AUTOSAR XML (schema 4-2-2)
package /STELLANTIS/EPT/ASWCs
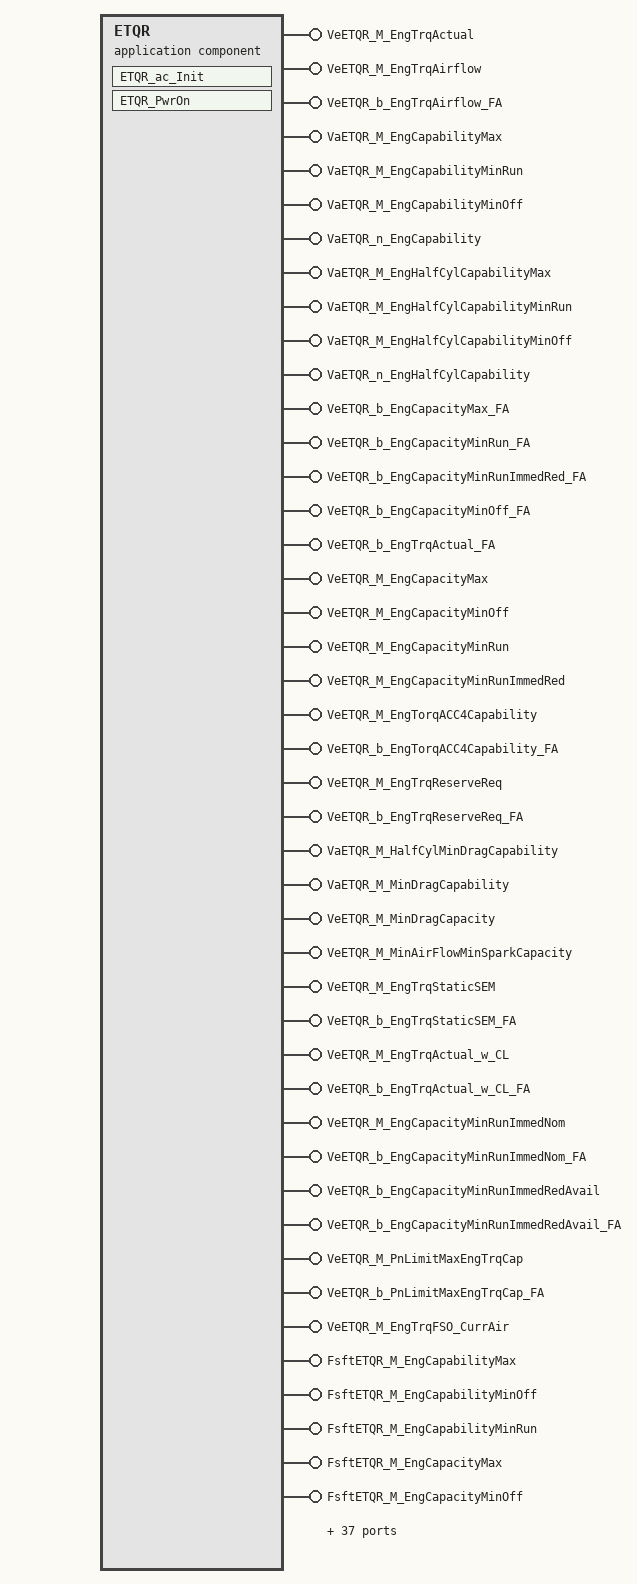
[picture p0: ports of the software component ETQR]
  application sw component type ETQR
    81 x provide port:
      VeETQR_M_EngTrqActual: nonqueued-sender-com-spec{data-element=Value, init-value=0}, provided-interface=VeETQR_M_EngTrqActual
      VeETQR_M_EngTrqAirflow: nonqueued-sender-com-spec{data-element=Value, init-value=0}, provided-interface=VeETQR_M_EngTrqAirflow
      VeETQR_b_EngTrqAirflow_FA: nonqueued-sender-com-spec{data-element=Value, init-value=0}, provided-interface=VeETQR_b_EngTrqAirflow_FA
      VaETQR_M_EngCapabilityMax: nonqueued-sender-com-spec{data-element=Value, init-value=16 x 0}, provided-interface=VaETQR_M_EngCapabilityMax
      VaETQR_M_EngCapabilityMinRun: nonqueued-sender-com-spec{data-element=Value, init-value=16 x 0}, provided-interface=VaETQR_M_EngCapabilityMinRun
      VaETQR_M_EngCapabilityMinOff: nonqueued-sender-com-spec{data-element=Value, init-value=16 x 0}, provided-interface=VaETQR_M_EngCapabilityMinOff
      VaETQR_n_EngCapability: nonqueued-sender-com-spec{data-element=Value, init-value=16 x 0}, provided-interface=VaETQR_n_EngCapability
      VaETQR_M_EngHalfCylCapabilityMax: nonqueued-sender-com-spec{data-element=Value, init-value=16 x 0}, provided-interface=VaETQR_M_EngHalfCylCapabilityMax
      VaETQR_M_EngHalfCylCapabilityMinRun: nonqueued-sender-com-spec{data-element=Value, init-value=16 x 0}, provided-interface=VaETQR_M_EngHalfCylCapabilityMinRun
      VaETQR_M_EngHalfCylCapabilityMinOff: nonqueued-sender-com-spec{data-element=Value, init-value=16 x 0}, provided-interface=VaETQR_M_EngHalfCylCapabilityMinOff
      VaETQR_n_EngHalfCylCapability: nonqueued-sender-com-spec{data-element=Value, init-value=16 x 0}, provided-interface=VaETQR_n_EngHalfCylCapability
      VeETQR_b_EngCapacityMax_FA: nonqueued-sender-com-spec{data-element=Value, init-value=0}, provided-interface=VeETQR_b_EngCapacityMax_FA
      VeETQR_b_EngCapacityMinRun_FA: nonqueued-sender-com-spec{data-element=Value, init-value=0}, provided-interface=VeETQR_b_EngCapacityMinRun_FA
      VeETQR_b_EngCapacityMinRunImmedRed_FA: nonqueued-sender-com-spec{data-element=Value, init-value=0}, provided-interface=VeETQR_b_EngCapacityMinRunImmedRed_FA
      VeETQR_b_EngCapacityMinOff_FA: nonqueued-sender-com-spec{data-element=Value, init-value=0}, provided-interface=VeETQR_b_EngCapacityMinOff_FA
      VeETQR_b_EngTrqActual_FA: nonqueued-sender-com-spec{data-element=Value, init-value=0}, provided-interface=VeETQR_b_EngTrqActual_FA
      VeETQR_M_EngCapacityMax: nonqueued-sender-com-spec{data-element=Value, init-value=0}, provided-interface=VeETQR_M_EngCapacityMax
      VeETQR_M_EngCapacityMinOff: nonqueued-sender-com-spec{data-element=Value, init-value=0}, provided-interface=VeETQR_M_EngCapacityMinOff
      VeETQR_M_EngCapacityMinRun: nonqueued-sender-com-spec{data-element=Value, init-value=0}, provided-interface=VeETQR_M_EngCapacityMinRun
      VeETQR_M_EngCapacityMinRunImmedRed: nonqueued-sender-com-spec{data-element=Value, init-value=0}, provided-interface=VeETQR_M_EngCapacityMinRunImmedRed
      VeETQR_M_EngTorqACC4Capability: nonqueued-sender-com-spec{data-element=Value, init-value=0}, provided-interface=VeETQR_M_EngTorqACC4Capability
      VeETQR_b_EngTorqACC4Capability_FA: nonqueued-sender-com-spec{data-element=Value, init-value=0}, provided-interface=VeETQR_b_EngTorqACC4Capability_FA
      VeETQR_M_EngTrqReserveReq: nonqueued-sender-com-spec{data-element=Value, init-value=0}, provided-interface=VeETQR_M_EngTrqReserveReq
      VeETQR_b_EngTrqReserveReq_FA: nonqueued-sender-com-spec{data-element=Value, init-value=0}, provided-interface=VeETQR_b_EngTrqReserveReq_FA
      VaETQR_M_HalfCylMinDragCapability: nonqueued-sender-com-spec{data-element=Value, init-value=16 x 0}, provided-interface=VaETQR_M_HalfCylMinDragCapability
      VaETQR_M_MinDragCapability: nonqueued-sender-com-spec{data-element=Value, init-value=16 x 0}, provided-interface=VaETQR_M_MinDragCapability
      VeETQR_M_MinDragCapacity: nonqueued-sender-com-spec{data-element=Value, init-value=0}, provided-interface=VeETQR_M_MinDragCapacity
      VeETQR_M_MinAirFlowMinSparkCapacity: nonqueued-sender-com-spec{data-element=Value, init-value=0}, provided-interface=VeETQR_M_MinAirFlowMinSparkCapacity
      VeETQR_M_EngTrqStaticSEM: nonqueued-sender-com-spec{data-element=Value, init-value=0}, provided-interface=VeETQR_M_EngTrqStaticSEM
      VeETQR_b_EngTrqStaticSEM_FA: nonqueued-sender-com-spec{data-element=Value, init-value=0}, provided-interface=VeETQR_b_EngTrqStaticSEM_FA
      VeETQR_M_EngTrqActual_w_CL: nonqueued-sender-com-spec{data-element=Value, init-value=0}, provided-interface=VeETQR_M_EngTrqActual_w_CL
      VeETQR_b_EngTrqActual_w_CL_FA: nonqueued-sender-com-spec{data-element=Value, init-value=0}, provided-interface=VeETQR_b_EngTrqActual_w_CL_FA
      VeETQR_M_EngCapacityMinRunImmedNom: nonqueued-sender-com-spec{data-element=Value, init-value=0}, provided-interface=VeETQR_M_EngCapacityMinRunImmedNom
      VeETQR_b_EngCapacityMinRunImmedNom_FA: nonqueued-sender-com-spec{data-element=Value, init-value=0}, provided-interface=VeETQR_b_EngCapacityMinRunImmedNom_FA
      VeETQR_b_EngCapacityMinRunImmedRedAvail: nonqueued-sender-com-spec{data-element=Value, init-value=0}, provided-interface=VeETQR_b_EngCapacityMinRunImmedRedAvail
      VeETQR_b_EngCapacityMinRunImmedRedAvail_FA: nonqueued-sender-com-spec{data-element=Value, init-value=0}, provided-interface=VeETQR_b_EngCapacityMinRunImmedRedAvail_FA
      VeETQR_M_PnLimitMaxEngTrqCap: nonqueued-sender-com-spec{data-element=Value, init-value=0}, provided-interface=VeETQR_M_PnLimitMaxEngTrqCap
      VeETQR_b_PnLimitMaxEngTrqCap_FA: nonqueued-sender-com-spec{data-element=Value, init-value=0}, provided-interface=VeETQR_b_PnLimitMaxEngTrqCap_FA
      VeETQR_M_EngTrqFSO_CurrAir: nonqueued-sender-com-spec{data-element=Value, init-value=0}, provided-interface=VeETQR_M_EngTrqFSO_CurrAir
      FsftETQR_M_EngCapabilityMax: server-com-spec=FsftETQR_M_EngCapabilityMax, provided-interface=FsftETQR_M_EngCapabilityMax
      FsftETQR_M_EngCapabilityMinOff: server-com-spec=FsftETQR_M_EngCapabilityMinOff, provided-interface=FsftETQR_M_EngCapabilityMinOff
      FsftETQR_M_EngCapabilityMinRun: server-com-spec=FsftETQR_M_EngCapabilityMinRun, provided-interface=FsftETQR_M_EngCapabilityMinRun
      FsftETQR_M_EngCapacityMax: server-com-spec=FsftETQR_M_EngCapacityMax, provided-interface=FsftETQR_M_EngCapacityMax
      FsftETQR_M_EngCapacityMinOff: server-com-spec=FsftETQR_M_EngCapacityMinOff, provided-interface=FsftETQR_M_EngCapacityMinOff
      FsftETQR_M_EngCapacityMinRun: server-com-spec=FsftETQR_M_EngCapacityMinRun, provided-interface=FsftETQR_M_EngCapacityMinRun
      FsftETQR_M_EngCapacityMinRunImmedNom: server-com-spec=FsftETQR_M_EngCapacityMinRunImmedNom, provided-interface=FsftETQR_M_EngCapacityMinRunImmedNom
      FsftETQR_M_EngCapacityMinRunImmedRed: server-com-spec=FsftETQR_M_EngCapacityMinRunImmedRed, provided-interface=FsftETQR_M_EngCapacityMinRunImmedRed
      FsftETQR_M_EngTorqACC4Capability: server-com-spec=FsftETQR_M_EngTorqACC4Capability, provided-interface=FsftETQR_M_EngTorqACC4Capability
      FsftETQR_M_EngTorque: server-com-spec=FsftETQR_M_EngTorque, provided-interface=FsftETQR_M_EngTorque
      FsftETQR_M_EngTrqActual: server-com-spec=FsftETQR_M_EngTrqActual, provided-interface=FsftETQR_M_EngTrqActual
      FsftETQR_M_EngTrqAirflow: server-com-spec=FsftETQR_M_EngTrqAirflow, provided-interface=FsftETQR_M_EngTrqAirflow
      FsftETQR_M_EngTrqFSO_CurrAir: server-com-spec=FsftETQR_M_EngTrqFSO_CurrAir, provided-interface=FsftETQR_M_EngTrqFSO_CurrAir
      FsftETQR_M_EngTrqReserveReq: server-com-spec=FsftETQR_M_EngTrqReserveReq, provided-interface=FsftETQR_M_EngTrqReserveReq
      FsftETQR_M_EngTrqStaticSEM: server-com-spec=FsftETQR_M_EngTrqStaticSEM, provided-interface=FsftETQR_M_EngTrqStaticSEM
      FsftETQR_M_MinAirFlowMinSparkCapacity: server-com-spec=FsftETQR_M_MinAirFlowMinSparkCapacity, provided-interface=FsftETQR_M_MinAirFlowMinSparkCapacity
      FsftETQR_M_MinDragCapability: server-com-spec=FsftETQR_M_MinDragCapability, provided-interface=FsftETQR_M_MinDragCapability
      FsftETQR_M_MinDragCapacity: server-com-spec=FsftETQR_M_MinDragCapacity, provided-interface=FsftETQR_M_MinDragCapacity
      FsftETQR_M_PnLimitMaxEngTrqCap: server-com-spec=FsftETQR_M_PnLimitMaxEngTrqCap, provided-interface=FsftETQR_M_PnLimitMaxEngTrqCap
      FsftETQR_b_EngCapacityMinRunImmedRedAvail: server-com-spec=FsftETQR_b_EngCapacityMinRunImmedRedAvail, provided-interface=FsftETQR_b_EngCapacityMinRunImmedRedAvail
      FsftETQR_n_EngCapability: server-com-spec=FsftETQR_n_EngCapability, provided-interface=FsftETQR_n_EngCapability
      PokeETQR_M_EngCapabilityMax: server-com-spec{operation=PokeETQR_M_EngCapabilityMax, queue-length=1}, provided-interface=PokeETQR_M_EngCapabilityMax
      PokeETQR_M_EngCapabilityMinOff: server-com-spec{operation=PokeETQR_M_EngCapabilityMinOff, queue-length=1}, provided-interface=PokeETQR_M_EngCapabilityMinOff
      PokeETQR_M_EngCapabilityMinRun: server-com-spec{operation=PokeETQR_M_EngCapabilityMinRun, queue-length=1}, provided-interface=PokeETQR_M_EngCapabilityMinRun
      PokeETQR_M_EngCapacityMax: server-com-spec{operation=PokeETQR_M_EngCapacityMax, queue-length=1}, provided-interface=PokeETQR_M_EngCapacityMax
      PokeETQR_M_EngCapacityMinOff: server-com-spec{operation=PokeETQR_M_EngCapacityMinOff, queue-length=1}, provided-interface=PokeETQR_M_EngCapacityMinOff
      PokeETQR_M_EngCapacityMinRun: server-com-spec{operation=PokeETQR_M_EngCapacityMinRun, queue-length=1}, provided-interface=PokeETQR_M_EngCapacityMinRun
      PokeETQR_M_EngCapacityMinRunImmedNom: server-com-spec{operation=PokeETQR_M_EngCapacityMinRunImmedNom, queue-length=1}, provided-interface=PokeETQR_M_EngCapacityMinRunImmedNom
      PokeETQR_M_EngCapacityMinRunImmedRed: server-com-spec{operation=PokeETQR_M_EngCapacityMinRunImmedRed, queue-length=1}, provided-interface=PokeETQR_M_EngCapacityMinRunImmedRed
      PokeETQR_M_EngTorqACC4Capability: server-com-spec{operation=PokeETQR_M_EngTorqACC4Capability, queue-length=1}, provided-interface=PokeETQR_M_EngTorqACC4Capability
      PokeETQR_M_EngTorque: server-com-spec{operation=PokeETQR_M_EngTorque, queue-length=1}, provided-interface=PokeETQR_M_EngTorque
      PokeETQR_M_EngTrqActual: server-com-spec{operation=PokeETQR_M_EngTrqActual, queue-length=1}, provided-interface=PokeETQR_M_EngTrqActual
      PokeETQR_M_EngTrqAirflow: server-com-spec{operation=PokeETQR_M_EngTrqAirflow, queue-length=1}, provided-interface=PokeETQR_M_EngTrqAirflow
      PokeETQR_M_EngTrqFSO_CurrAir: server-com-spec{operation=PokeETQR_M_EngTrqFSO_CurrAir, queue-length=1}, provided-interface=PokeETQR_M_EngTrqFSO_CurrAir
      PokeETQR_M_EngTrqReserveReq: server-com-spec{operation=PokeETQR_M_EngTrqReserveReq, queue-length=1}, provided-interface=PokeETQR_M_EngTrqReserveReq
      PokeETQR_M_EngTrqStaticSEM: server-com-spec{operation=PokeETQR_M_EngTrqStaticSEM, queue-length=1}, provided-interface=PokeETQR_M_EngTrqStaticSEM
      PokeETQR_M_MinAirFlowMinSparkCapacity: server-com-spec{operation=PokeETQR_M_MinAirFlowMinSparkCapacity, queue-length=1}, provided-interface=PokeETQR_M_MinAirFlowMinSparkCapacity
      PokeETQR_M_MinDragCapability: server-com-spec{operation=PokeETQR_M_MinDragCapability, queue-length=1}, provided-interface=PokeETQR_M_MinDragCapability
      PokeETQR_M_MinDragCapacity: server-com-spec{operation=PokeETQR_M_MinDragCapacity, queue-length=1}, provided-interface=PokeETQR_M_MinDragCapacity
      PokeETQR_M_PnLimitMaxEngTrqCap: server-com-spec{operation=PokeETQR_M_PnLimitMaxEngTrqCap, queue-length=1}, provided-interface=PokeETQR_M_PnLimitMaxEngTrqCap
      PokeETQR_b_EngCapacityMinRunImmedRedAvail: server-com-spec{operation=PokeETQR_b_EngCapacityMinRunImmedRedAvail, queue-length=1}, provided-interface=PokeETQR_b_EngCapacityMinRunImmedRedAvail
      PokeETQR_n_EngCapability: server-com-spec{operation=PokeETQR_n_EngCapability, queue-length=1}, provided-interface=PokeETQR_n_EngCapability
    behavior IB_ETQR: data-type-mapping=msADTtoIDTMapping, handle-termination-and-restart=NO-SUPPORT
      init event Event_ETQR_ac_Init: start-on-event=ETQR_ac_Init
      init event Event_PwrOn: start-on-event=ETQR_PwrOn
      explicit-inter-runnable-variables:
        40 x data, all with sw-calibration-access=READ-ONLY:
          VeETQI_M_EngTrqActual_write_IRV: category=VALUE, type=Float, init-value=0
          VeETQI_b_EngTrqActual_FA_write_IRV: category=VALUE, type=Boolean, init-value=0
          VeETQI_b_EngTrqAirflow_FA_write_IRV: category=VALUE, type=Boolean, init-value=0
          VeETQI_M_EngTrqAirflow_write_IRV: category=VALUE, type=Float, init-value=0
          VeETQI_M_EngTrqStaticSEM_write_IRV: category=VALUE, type=Float, init-value=0
          VeETQI_b_EngTrqStaticSEM_FA_write_IRV: category=VALUE, type=Boolean, init-value=0
          VeETQI_M_EngTorque_write_IRV: category=VALUE, type=Float, init-value=0
          VeETQI_b_EngTorque_FA_write_IRV: category=VALUE, type=Boolean, init-value=0
          VeETQI_b_EngCapacityMax_FA_write_IRV: category=VALUE, type=Boolean, init-value=0
          EngCapabilityMax_x10ms_write_IRV: category=ARRAY, type=rt_Array_Float_16, init-value=16 x 0
          VeETQI_M_EngCapacityMax_write_IRV: category=VALUE, type=Float, init-value=0
          VeETQI_b_EngCapacityMinOff_FA_write_IRV: category=VALUE, type=Boolean, init-value=0
          VeETQI_b_EngCapacityMinRunImmed_FA_write_IRV: category=VALUE, type=Boolean, init-value=0
          VeETQI_b_EngCapacityMinRun_FA_write_IRV: category=VALUE, type=Boolean, init-value=0
          VeETQI_M_EngCapacityMinRun_write_IRV: category=VALUE, type=Float, init-value=0
          VeETQI_M_EngCapacityMinRunImmed_write_IRV: category=VALUE, type=Float, init-value=0
          VeETQI_M_EngCapacityMinOff_write_IRV: category=VALUE, type=Float, init-value=0
          VaETQI_M_EngCapabilityMinRun_write_IRV: category=ARRAY, type=rt_Array_Float_16, init-value=16 x 0
          EngCapabilityMinOff_x10ms_write_IRV: category=ARRAY, type=rt_Array_Float_16, init-value=16 x 0
          VaETQI_n_EngCapability_write_IRV: category=ARRAY, type=rt_Array_Float_16, init-value=16 x 0
          EngHalfCylCapabilityMax_x10ms_write_IRV: category=ARRAY, type=rt_Array_Float_16, init-value=16 x 0
          VaETQI_M_EngHalfCylCapabilityMinRun_write_IRV: category=ARRAY, type=rt_Array_Float_16, init-value=16 x 0
          EngHalfCylCapabilityMinOff_x10ms_write_IRV: category=ARRAY, type=rt_Array_Float_16, init-value=16 x 0
          VaETQI_n_EngHalfCylCapability_write_IRV: category=ARRAY, type=rt_Array_Float_16, init-value=16 x 0
          VeETQI_M_MinDragCapacity_write_IRV: category=VALUE, type=Float, init-value=0
          VeETQI_b_MinDragCapacity_FA_write_IRV: category=VALUE, type=Boolean, init-value=0
          VaETQI_M_MinDragCapability_write_IRV: category=ARRAY, type=rt_Array_Float_16, init-value=16 x 0
          VaETQI_M_HalfCylMinDragCapability_write_IRV: category=ARRAY, type=rt_Array_Float_16, init-value=16 x 0
          VeETQI_M_MinAirFlowMinSparkCapacity_write_IRV: category=VALUE, type=Float, init-value=0
          VeETQI_b_MinAirFlowMinSparkCapacity_FA_write_IRV: category=VALUE, type=Boolean, init-value=0
          VeETQI_M_EngCapacityMinRunImmedNom_write_IRV: category=VALUE, type=Float, init-value=0
          VeETQI_b_EngCapacityMinRunImmedNom_FA_write_IRV: category=VALUE, type=Boolean, init-value=0
          VaETQI_M_EngCapabilityMax_write_IRV: category=ARRAY, type=rt_Array_Float_16, init-value=16 x 0
          VeETQI_Cnt_CapabilityFrame_Max_write_IRV: category=VALUE, type=Float, init-value=0
          VaETQI_M_EngHalfCylCapabilityMax_write_IRV: category=ARRAY, type=rt_Array_Float_16, init-value=16 x 0
          VeETQI_Cnt_CapabilityFrame_HalfCylMax_write_IRV: category=VALUE, type=Float, init-value=0
          VaETQI_M_EngCapabilityMinOff_write_IRV: category=ARRAY, type=rt_Array_Float_16, init-value=16 x 0
          VeETQI_Cnt_CapabilityFrame_Min_write_IRV: category=VALUE, type=Float, init-value=0
          VaETQI_M_EngHalfCylCapabilityMinOff_write_IRV: category=ARRAY, type=rt_Array_Float_16, init-value=16 x 0
          VeETQI_Cnt_CapabilityFrame_HalfCylMin_write_IRV: category=VALUE, type=Float, init-value=0
      runnable ETQR_ac_Init
        data-send-points:
          10 x access:
            OUT_VaETQR_M_EngCapabilityMax_Value: accessed-variable=VaETQR_M_EngCapabilityMax.Value
            OUT_VaETQR_M_EngCapabilityMinRun_Value: accessed-variable=VaETQR_M_EngCapabilityMinRun.Value
            OUT_VaETQR_M_EngCapabilityMinOff_Value: accessed-variable=VaETQR_M_EngCapabilityMinOff.Value
            OUT_VaETQR_n_EngCapability_Value: accessed-variable=VaETQR_n_EngCapability.Value
            OUT_VaETQR_M_EngHalfCylCapabilityMax_Value: accessed-variable=VaETQR_M_EngHalfCylCapabilityMax.Value
            OUT_VaETQR_M_EngHalfCylCapabilityMinRun_Value: accessed-variable=VaETQR_M_EngHalfCylCapabilityMinRun.Value
            OUT_VaETQR_M_EngHalfCylCapabilityMinOff_Value: accessed-variable=VaETQR_M_EngHalfCylCapabilityMinOff.Value
            OUT_VaETQR_n_EngHalfCylCapability_Value: accessed-variable=VaETQR_n_EngHalfCylCapability.Value
            OUT_VaETQR_M_HalfCylMinDragCapability_Value: accessed-variable=VaETQR_M_HalfCylMinDragCapability.Value
            OUT_VaETQR_M_MinDragCapability_Value: accessed-variable=VaETQR_M_MinDragCapability.Value
      runnable ETQR_PwrOn
        data-send-points:
          39 x access:
            OUT_VaETQR_M_EngCapabilityMinRun_Value: accessed-variable=VaETQR_M_EngCapabilityMinRun.Value
            OUT_VeETQR_b_PnLimitMaxEngTrqCap_FA_Value: accessed-variable=VeETQR_b_PnLimitMaxEngTrqCap_FA.Value
            OUT_VeETQR_M_PnLimitMaxEngTrqCap_Value: accessed-variable=VeETQR_M_PnLimitMaxEngTrqCap.Value
            OUT_VaETQR_M_EngHalfCylCapabilityMinRun_Value: accessed-variable=VaETQR_M_EngHalfCylCapabilityMinRun.Value
            OUT_VaETQR_n_EngCapability_Value: accessed-variable=VaETQR_n_EngCapability.Value
            OUT_VaETQR_n_EngHalfCylCapability_Value: accessed-variable=VaETQR_n_EngHalfCylCapability.Value
            OUT_VaETQR_M_MinDragCapability_Value: accessed-variable=VaETQR_M_MinDragCapability.Value
            OUT_VaETQR_M_HalfCylMinDragCapability_Value: accessed-variable=VaETQR_M_HalfCylMinDragCapability.Value
            OUT_VeETQR_b_EngCapacityMinRunImmedRedAvail_Value: accessed-variable=VeETQR_b_EngCapacityMinRunImmedRedAvail.Value
            OUT_VeETQR_b_EngCapacityMinRunImmedRedAvail_FA_Value: accessed-variable=VeETQR_b_EngCapacityMinRunImmedRedAvail_FA.Value
            OUT_VeETQR_b_EngCapacityMax_FA_Value: accessed-variable=VeETQR_b_EngCapacityMax_FA.Value
            OUT_VeETQR_b_EngCapacityMinRun_FA_Value: accessed-variable=VeETQR_b_EngCapacityMinRun_FA.Value
            OUT_VeETQR_b_EngCapacityMinRunImmedRed_FA_Value: accessed-variable=VeETQR_b_EngCapacityMinRunImmedRed_FA.Value
            OUT_VeETQR_b_EngCapacityMinOff_FA_Value: accessed-variable=VeETQR_b_EngCapacityMinOff_FA.Value
            OUT_VeETQR_b_EngTrqActual_FA_Value: accessed-variable=VeETQR_b_EngTrqActual_FA.Value
            OUT_VeETQR_b_EngTrqAirflow_FA_Value: accessed-variable=VeETQR_b_EngTrqAirflow_FA.Value
            OUT_VeETQR_M_EngTorqACC4Capability_Value: accessed-variable=VeETQR_M_EngTorqACC4Capability.Value
            OUT_VeETQR_b_EngTorqACC4Capability_FA_Value: accessed-variable=VeETQR_b_EngTorqACC4Capability_FA.Value
            OUT_VeETQR_b_EngTrqReserveReq_FA_Value: accessed-variable=VeETQR_b_EngTrqReserveReq_FA.Value
            OUT_VeETQR_M_EngTrqReserveReq_Value: accessed-variable=VeETQR_M_EngTrqReserveReq.Value
            OUT_VeETQR_M_EngTrqActual_Value: accessed-variable=VeETQR_M_EngTrqActual.Value
            OUT_VeETQR_M_EngTrqAirflow_Value: accessed-variable=VeETQR_M_EngTrqAirflow.Value
            OUT_VeETQR_b_EngTrqStaticSEM_FA_Value: accessed-variable=VeETQR_b_EngTrqStaticSEM_FA.Value
            OUT_VeETQR_M_EngTrqStaticSEM_Value: accessed-variable=VeETQR_M_EngTrqStaticSEM.Value
            OUT_VeETQR_M_MinAirFlowMinSparkCapacity_Value: accessed-variable=VeETQR_M_MinAirFlowMinSparkCapacity.Value
            OUT_VeETQR_M_MinDragCapacity_Value: accessed-variable=VeETQR_M_MinDragCapacity.Value
            OUT_VeETQR_M_EngCapacityMinRunImmedRed_Value: accessed-variable=VeETQR_M_EngCapacityMinRunImmedRed.Value
            OUT_VeETQR_M_EngCapacityMinRun_Value: accessed-variable=VeETQR_M_EngCapacityMinRun.Value
            OUT_VeETQR_b_EngCapacityMinRunImmedNom_FA_Value: accessed-variable=VeETQR_b_EngCapacityMinRunImmedNom_FA.Value
            OUT_VeETQR_M_EngCapacityMinRunImmedNom_Value: accessed-variable=VeETQR_M_EngCapacityMinRunImmedNom.Value
            OUT_VaETQR_M_EngCapabilityMax_Value: accessed-variable=VaETQR_M_EngCapabilityMax.Value
            OUT_VaETQR_M_EngCapabilityMinOff_Value: accessed-variable=VaETQR_M_EngCapabilityMinOff.Value
            OUT_VaETQR_M_EngHalfCylCapabilityMax_Value: accessed-variable=VaETQR_M_EngHalfCylCapabilityMax.Value
            OUT_VaETQR_M_EngHalfCylCapabilityMinOff_Value: accessed-variable=VaETQR_M_EngHalfCylCapabilityMinOff.Value
            OUT_VeETQR_M_EngCapacityMax_Value: accessed-variable=VeETQR_M_EngCapacityMax.Value
            OUT_VeETQR_M_EngCapacityMinOff_Value: accessed-variable=VeETQR_M_EngCapacityMinOff.Value
            OUT_VeETQR_M_EngTrqActual_w_CL_Value: accessed-variable=VeETQR_M_EngTrqActual_w_CL.Value
            OUT_VeETQR_b_EngTrqActual_w_CL_FA_Value: accessed-variable=VeETQR_b_EngTrqActual_w_CL_FA.Value
            OUT_VeETQR_M_EngTrqFSO_CurrAir_Value: accessed-variable=VeETQR_M_EngTrqFSO_CurrAir.Value
        written-local-variables:
          40 x access:
            WV_EngCapabilityMax_x10ms_write_IRV: accessed-variable=EngCapabilityMax_x10ms_write_IRV
            WV_EngCapabilityMinOff_x10ms_write_IRV: accessed-variable=EngCapabilityMinOff_x10ms_write_IRV
            WV_EngHalfCylCapabilityMax_x10ms_write_IRV: accessed-variable=EngHalfCylCapabilityMax_x10ms_write_IRV
            WV_EngHalfCylCapabilityMinOff_x10ms_write_IRV: accessed-variable=EngHalfCylCapabilityMinOff_x10ms_write_IRV
            WV_VaETQI_M_EngCapabilityMax_write_IRV: accessed-variable=VaETQI_M_EngCapabilityMax_write_IRV
            WV_VaETQI_M_EngCapabilityMinOff_write_IRV: accessed-variable=VaETQI_M_EngCapabilityMinOff_write_IRV
            WV_VaETQI_M_EngCapabilityMinRun_write_IRV: accessed-variable=VaETQI_M_EngCapabilityMinRun_write_IRV
            WV_VaETQI_M_EngHalfCylCapabilityMax_write_IRV: accessed-variable=VaETQI_M_EngHalfCylCapabilityMax_write_IRV
            WV_VaETQI_M_EngHalfCylCapabilityMinOff_write_IRV: accessed-variable=VaETQI_M_EngHalfCylCapabilityMinOff_write_IRV
            WV_VaETQI_M_EngHalfCylCapabilityMinRun_write_IRV: accessed-variable=VaETQI_M_EngHalfCylCapabilityMinRun_write_IRV
            WV_VaETQI_M_HalfCylMinDragCapability_write_IRV: accessed-variable=VaETQI_M_HalfCylMinDragCapability_write_IRV
            WV_VaETQI_M_MinDragCapability_write_IRV: accessed-variable=VaETQI_M_MinDragCapability_write_IRV
            WV_VaETQI_n_EngCapability_write_IRV: accessed-variable=VaETQI_n_EngCapability_write_IRV
            WV_VaETQI_n_EngHalfCylCapability_write_IRV: accessed-variable=VaETQI_n_EngHalfCylCapability_write_IRV
            WV_VeETQI_Cnt_CapabilityFrame_HalfCylMax_write_IRV: accessed-variable=VeETQI_Cnt_CapabilityFrame_HalfCylMax_write_IRV
            WV_VeETQI_Cnt_CapabilityFrame_HalfCylMin_write_IRV: accessed-variable=VeETQI_Cnt_CapabilityFrame_HalfCylMin_write_IRV
            WV_VeETQI_Cnt_CapabilityFrame_Max_write_IRV: accessed-variable=VeETQI_Cnt_CapabilityFrame_Max_write_IRV
            WV_VeETQI_Cnt_CapabilityFrame_Min_write_IRV: accessed-variable=VeETQI_Cnt_CapabilityFrame_Min_write_IRV
            WV_VeETQI_M_EngCapacityMax_write_IRV: accessed-variable=VeETQI_M_EngCapacityMax_write_IRV
            WV_VeETQI_M_EngCapacityMinOff_write_IRV: accessed-variable=VeETQI_M_EngCapacityMinOff_write_IRV
            WV_VeETQI_M_EngCapacityMinRunImmedNom_write_IRV: accessed-variable=VeETQI_M_EngCapacityMinRunImmedNom_write_IRV
            WV_VeETQI_M_EngCapacityMinRunImmed_write_IRV: accessed-variable=VeETQI_M_EngCapacityMinRunImmed_write_IRV
            WV_VeETQI_M_EngCapacityMinRun_write_IRV: accessed-variable=VeETQI_M_EngCapacityMinRun_write_IRV
            WV_VeETQI_M_EngTorque_write_IRV: accessed-variable=VeETQI_M_EngTorque_write_IRV
            WV_VeETQI_M_EngTrqActual_write_IRV: accessed-variable=VeETQI_M_EngTrqActual_write_IRV
            WV_VeETQI_M_EngTrqAirflow_write_IRV: accessed-variable=VeETQI_M_EngTrqAirflow_write_IRV
            WV_VeETQI_M_EngTrqStaticSEM_write_IRV: accessed-variable=VeETQI_M_EngTrqStaticSEM_write_IRV
            WV_VeETQI_M_MinAirFlowMinSparkCapacity_write_IRV: accessed-variable=VeETQI_M_MinAirFlowMinSparkCapacity_write_IRV
            WV_VeETQI_M_MinDragCapacity_write_IRV: accessed-variable=VeETQI_M_MinDragCapacity_write_IRV
            WV_VeETQI_b_EngCapacityMax_FA_write_IRV: accessed-variable=VeETQI_b_EngCapacityMax_FA_write_IRV
            WV_VeETQI_b_EngCapacityMinOff_FA_write_IRV: accessed-variable=VeETQI_b_EngCapacityMinOff_FA_write_IRV
            WV_VeETQI_b_EngCapacityMinRunImmedNom_FA_write_IRV: accessed-variable=VeETQI_b_EngCapacityMinRunImmedNom_FA_write_IRV
            WV_VeETQI_b_EngCapacityMinRunImmed_FA_write_IRV: accessed-variable=VeETQI_b_EngCapacityMinRunImmed_FA_write_IRV
            WV_VeETQI_b_EngCapacityMinRun_FA_write_IRV: accessed-variable=VeETQI_b_EngCapacityMinRun_FA_write_IRV
            WV_VeETQI_b_EngTorque_FA_write_IRV: accessed-variable=VeETQI_b_EngTorque_FA_write_IRV
            WV_VeETQI_b_EngTrqActual_FA_write_IRV: accessed-variable=VeETQI_b_EngTrqActual_FA_write_IRV
            WV_VeETQI_b_EngTrqAirflow_FA_write_IRV: accessed-variable=VeETQI_b_EngTrqAirflow_FA_write_IRV
            WV_VeETQI_b_EngTrqStaticSEM_FA_write_IRV: accessed-variable=VeETQI_b_EngTrqStaticSEM_FA_write_IRV
            WV_VeETQI_b_MinAirFlowMinSparkCapacity_FA_write_IRV: accessed-variable=VeETQI_b_MinAirFlowMinSparkCapacity_FA_write_IRV
            WV_VeETQI_b_MinDragCapacity_FA_write_IRV: accessed-variable=VeETQI_b_MinDragCapacity_FA_write_IRV
      variation point proxy Variant_ETQR_1: category=CONDITION, condition-access=0
